# nrf54h20_enga_sysctrl register map
Vendor: Nordic Semiconductor; Series: nRF54h; File version: 1
Registers are 32-bit, read-write, reset 0x0 unless marked. A register's access mark holds for its fields unless they carry their own. Offsets are from the block's base; [hi:lo] are bit positions; lines under a group give offsets from that group; {n}, {i} and the like mark numbered series; 'fields as' and 'values as' point back to an identical list.

## GLOBAL_GPIOINTERNAL_NS — GPIO Internal 0
Base 0x4F939E00
Same registers: GLOBAL_GPIOINTERNAL_S 0x5F939E00
0x40 LATCHCLRWAITCNT reset 0x2 — Select the number of wait cycles inserted on the bus when a LATCH register is cleared.
  [1:0] LATCHCLRWAITCNT
0x44 FORCELDETECTLOWCNT reset 0x8 — Select the number of cycles that LDETECT is forced low after clearing a LATCH register.
  [3:0] FORCELDETECTLOWCNT
0x48 RESET — Reset all GPIO registers.
  [0] RESET
    1=RESET (Trigger reset); 0=NA (No effect)
0x4C SENSECONFIGCHANGECNT reset 0x3 — Selects the number of cycles before the SENSE configuration takes effect when it is changed. Setting this register lower than the reset value can lead to unwanted LATCH set when SENSE and INPUT fields (PIN[n].CNF) are changed simultaneously.
  [2:0] SENSECONFIGCHANGECNT — Selects the number of cycles before the SENSE configuration takes effect when it is changed.
0x160 PCGC group — Unspecified
  0x00 TURNOFFAUTOCLOCKSOURCEREQ ro — No functionality
  {0x20+4j} PENALTY[{j}] (j=0..4) ro — Description collection: Penalty level for power/clock pair n
    [7:0] PENALTY — Penalty level
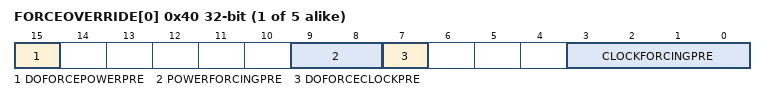
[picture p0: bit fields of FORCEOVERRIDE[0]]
  {0x40+4j} FORCEOVERRIDE[{j}] (j=0..4) ro — Description collection: Force override of power/clock pair n
    [15] DOFORCEPOWERPRE, [9:8] POWERFORCINGPRE, [7] DOFORCECLOCKPRE, [3:0] CLOCKFORCINGPRE

## GGENERIC18_S — GENERIC
Base 0x5F952000
0x00 TASKS_GENERICTASK wo — Generic event
  [0] TASKS_GENERICTASK
    1=Trigger task
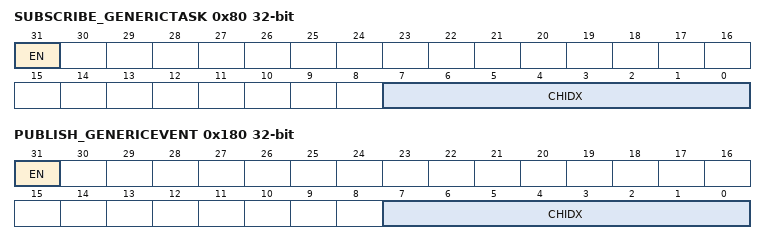
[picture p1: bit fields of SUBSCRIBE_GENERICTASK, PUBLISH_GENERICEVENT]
0x80 SUBSCRIBE_GENERICTASK — Subscribe configuration for task GENERICTASK
  [31] EN
    0=Disabled (Disable subscription); 1=Enabled (Enable subscription)
  [7:0] CHIDX — DPPI channel that task GENERICTASK will subscribe to
0x100 EVENTS_GENERICEVENT — Generic event
  [0] EVENTS_GENERICEVENT
    0=NotGenerated (Event not generated); 1=Generated (Event generated)
0x180 PUBLISH_GENERICEVENT — Publish configuration for event GENERICEVENT
  [31] EN
    0=Disabled (Disable publishing); 1=Enabled (Enable publishing)
  [7:0] CHIDX — DPPI channel that event GENERICEVENT will publish to
0x300 INTEN — Enable or disable interrupt
  [0] GENERICEVENT — Enable or disable interrupt for event GENERICEVENT
    0=Disabled; 1=Enabled
0x304 INTENSET — Enable interrupt
  [0] GENERICEVENT — Write '1' to enable interrupt for event GENERICEVENT
    on read: 0=Disabled (Read: Disabled); 1=Enabled (Read: Enabled) | on write: 1=Set (Enable)
0x308 INTENCLR — Disable interrupt
  [0] GENERICEVENT — Write '1' to disable interrupt for event GENERICEVENT
    on read: 0=Disabled (Read: Disabled); 1=Enabled (Read: Enabled) | on write: 1=Clear (Disable)

## VREGSU_S — VREGSU peripheral
Base 0x5F966000
0x480 PWRUPCTRL — Power up control
  [0] CTRL
    0=PowerDown; 1=PowerUp
0x600 DFT group — Unspecified
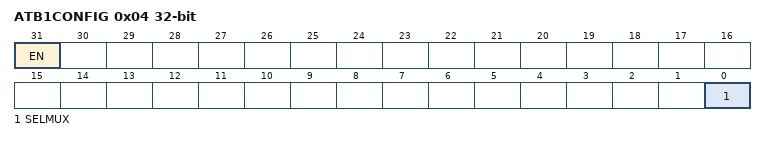
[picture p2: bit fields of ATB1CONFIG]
  0x04 ATB1CONFIG — Analog Test Bus 1 (ATB1) configuration
    [31] EN — Enable the analog test bus
      0=Disabled (Analog test bus is disabled); 1=Enabled (Analog test bus is enabled)
    [0] SELMUX — Select multiplexer for ATB1
      0=Spare0 (HiZ. For future use); 1=VFB1V2 (VDD_AO_1V8 scaled by 2/3)

## OSCRFR_S — OSCRFR peripheral
Base 0x5F96B000
0x400 STATUS ro
  [0] MODE — Current oscillator mode
    0=Normal mode; 1=Bypass mode
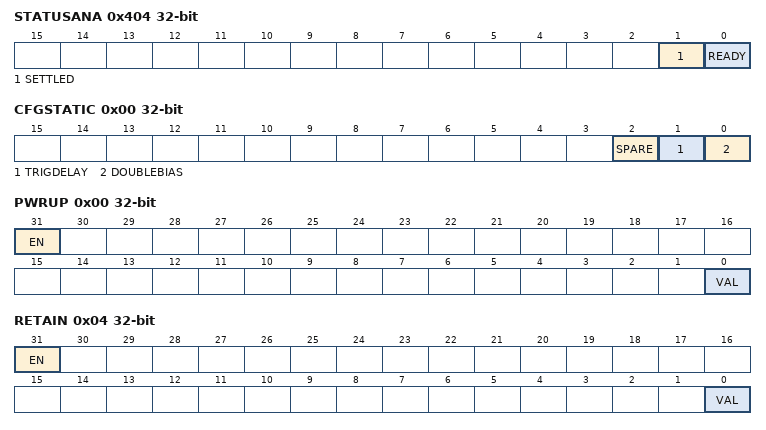
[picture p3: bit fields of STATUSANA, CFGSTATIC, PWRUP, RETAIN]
0x404 STATUSANA ro — Status of analog module output signals
  [1] SETTLED — Current value of the SETTLED signal from the analog module
  [0] READY — Current value of the READY signal from the analog module
0x410 CONFIG group — Unspecified
  0x00 CFGSTATIC — OSCRFR static CFG configuration
    [2] SPARE
    [1] TRIGDELAY — Increase TRIG signal delay
      0=Disabled; 1=Enabled
    [0] DOUBLEBIAS — Enable double bias
      0=Disabled; 1=Enabled
0x440 TRIM group — Unspecified
  0x00 OSC — Oscillation period trimming
    [2:0] VAL — Oscillation period trimming value
      0=Normal trim value; 1=The trim value is 35 percent; 2=The trim value is 154 percent; 3=The trim value is 670 percent; 4=ValNeg51 (The trim value is -54 percent); 5=ValNeg42 (The trim value is -49 percent); 6=ValNeg31 (The trim value is -37 percent); 7=ValNeg18 (The trim value is -26 percent)
  0x04 IBPSR — IBPSR current trimming
    [3:0] VAL — IBPSR current and VREF voltage trimming value
0x480 MIRROR reset 0x1 — Enable LOCK for mirrored registers
  [0] LOCK — Lock for mirrored registers
    0=Disabled (Lock disabled); 1=Enabled (Lock enabled)
0x484 MODE — Oscillator mode
  [1:0] MODE
    0=Automatically handled by the peripheral; 1=Normal mode - Use internal oscillator; 2=Bypass mode - Use OSC_RFR_DIG_AO_0V8 signal
0x500 OVERRIDE group — Unspecified
  0x00 PWRUP — Override the PWRUP signal to the analog module
    [31] EN — Enable the override
      0=Disabled (Override is disabled); 1=Enabled (Override is enabled)
    [0] VAL — Override value for the signal
  0x04 RETAIN — Override the RETAIN signal to the analog module
    fields as OVERRIDE.PWRUP
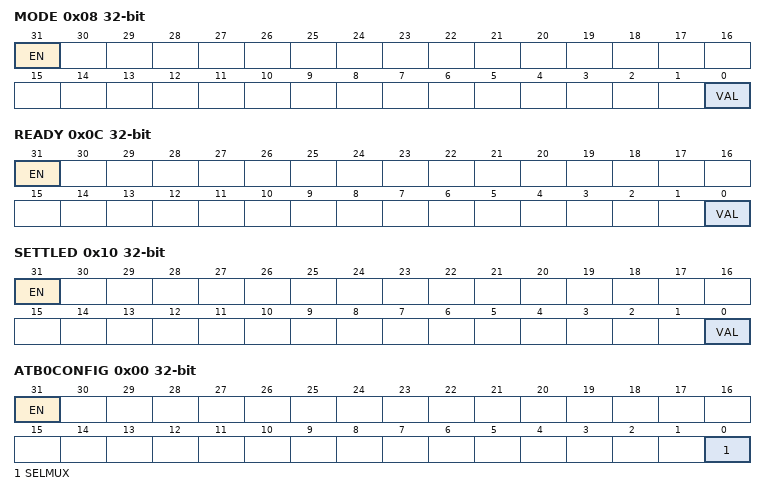
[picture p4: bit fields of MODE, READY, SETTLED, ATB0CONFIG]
  0x08 MODE — Override the MODE signal to the analog module
    fields as OVERRIDE.PWRUP
  0x0C READY — Override the READY signal from the analog module
    [31] EN — Enable the override
      values as OVERRIDE.PWRUP.EN
    [0] VAL — Current value of the signal
  0x10 SETTLED — Override the SETTLED signal from the analog module
    fields as OVERRIDE.READY
0x600 DFT group — Unspecified
  0x00 ATB0CONFIG — Analog Test Bus 0 (ATB0) configuration
    [31] EN — Enable the analog test bus
      0=Disabled (Analog test bus is disabled); 1=Enabled (Analog test bus is enabled)
    [0] SELMUX — Select multiplexer for ATB0
      0=IBPSR4U (IBPSR_4U signal selected); 1=IBPP50N (IBPP_50N signal selected)
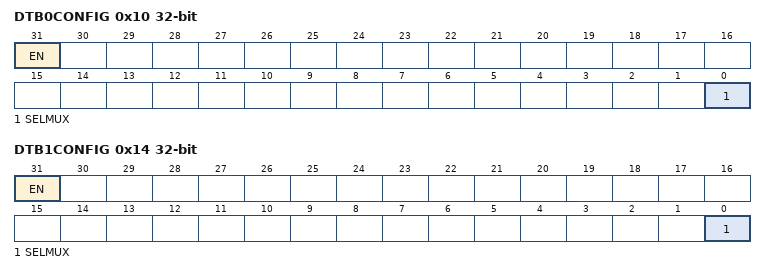
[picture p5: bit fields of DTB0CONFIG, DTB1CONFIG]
  0x10 DTB0CONFIG — Digital Test Bus 0 (DTB0) configuration
    [31] EN — Enable the digital test bus
      0=Disabled (Digital test bus is disabled); 1=Enabled (Digital test bus is enabled)
    [0] SELMUX — Select multiplexer for DTB0
      0=READY (READY signal selected); 1=OSC (OSC_RFR_ANA_AO_0V8 signal selected)
  0x14 DTB1CONFIG — Digital Test Bus 1 (DTB1) configuration
    [31] EN — Enable the digital test bus
      values as DFT.DTB0CONFIG.EN
    [0] SELMUX — Select multiplexer for DTB1
      0=SETTLED (SETTLED signal selected); 1=OSC (OSC_RFR_ANA_AO_0V8 signal selected)
  0x1C DTB3CONFIG — Digital Test Bus 3 (DTB3) configuration
    [27] PWRUPDELTEST — Enable the PWRUP delay test circuit
      0=Disabled (PWRUP delay test circuit is disabled); 1=Enabled (PWRUP delay test circuit is enabled)
  0x30 TCFG — Test mode configuration
    [0] BIASCURRENT — Enable continuous mode for measuring bias current over ATB
      0=Disabled; 1=Enabled

## SWEXT_S — SWEXT peripheral
Base 0x5F96C000
0x400 CONTROL — Switch control for the 1.8V supply to external circuit
  [0] ENABLE — Enable for the switch
    0=Disable (Switch disabled); 1=Enable (Switch enabled)

## VDETIO_S — VDETIO peripheral
Base 0x5F974000
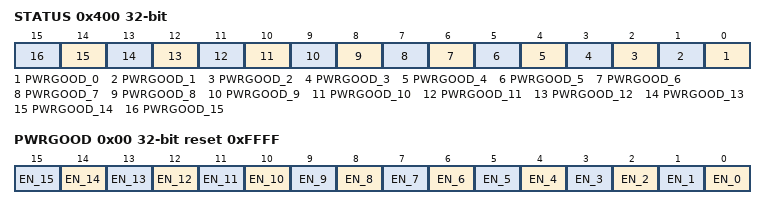
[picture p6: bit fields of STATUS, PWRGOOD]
0x400 STATUS ro — Voltage detector status
  [all] fields
    0=AboveThr (Power good detector detected voltage above threshold level); 1=BelowThr (Power good detector detected voltage below threshold level)
  [n] PWRGOOD_{n} (n=0..15) — Power good detector status for port [{n}]
0x410 CONFIG group — Unspecified
  0x00 PWRGOOD reset 0xFFFF — Power good detector configuration
    [all] fields
      0=Disabled (IO voltage detector is disabled); 1=Enabled (IO voltage detector is enabled)
    [n] EN_{n} (n=0..15) — Enable the power good detector for port [{n}]
